# N32H7xx register map
Vendor: Nationstech Ltd.; File version: 1.0
CPU: CM7 r1p1, little endian, MPU, FPU, 4 interrupt priority bits
Registers are 32-bit, read-write, reset 0x0 unless marked. A register's access mark holds for its fields unless they carry their own. Offsets are from the block's base; [hi:lo] are bit positions; {n}, {i} and the like mark numbered series; 'fields as' and 'values as' point back to an identical list.

## CORDIC — CORDIC Processors
Base 0x400F1000
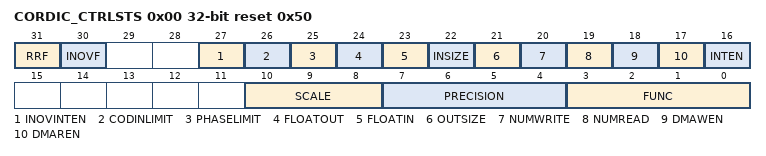
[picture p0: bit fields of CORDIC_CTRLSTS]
0x00 CORDIC_CTRLSTS reset 0x50 — CORDIC Control Status Register
  [31] RRF ro — Result Ready Flag
  [30] INOVF — Input Overflow Flag
  [27] INOVINTEN — Input Overflow Interrupt Control Bit
  [26] CODINLIMIT — Coordinate Output Limit Control
  [25] PHASELIMIT — Phase Output Limit Control
  [24] FLOATOUT — Floating-point Fixed-point Output Control
  [23] FLOATIN — Floating-point Fixed-point Input Control.
  [22] INSIZE — Input Data Width
  [21] OUTSIZE — Output Data Width
  [20] NUMWRITE — CORDIC_WDAT Register Parameter Count
  [19] NUMREAD — Number of results that can be read from the CORDIC_RDAT register
  [18] DMAWEN — DMA Write Request Enable
  [17] DMAREN — DMA Read Request Enable
  [16] INTEN — Interrupt Enable
  [10:8] SCALE — Scaling Factor
  [7:4] PRECISION — Iteration Count
  [3:0] FUNC — Functions
0x04 CORDIC_WDAT wo — CORDIC Write Data Register
  [31:0] WDAT — Write Data
0x08 CORDIC_RDAT ro — CORDIC Read Data Register
  [31:0] RDAT — Read Data

## DCMUA — DCMU processor A side
Base 0x400F7000
{0x0+4i} DCMUA_TXMSG{i} wo (i=0..3) — DCMU processor A transmit message register {i}
  [31:0] DATA — Transmit message data
{0x10+4i} DCMUA_RCVMSG{i} ro (i=0..3) — DCMU processor A receive message register {i}
  [31:0] DATA — Receive message data
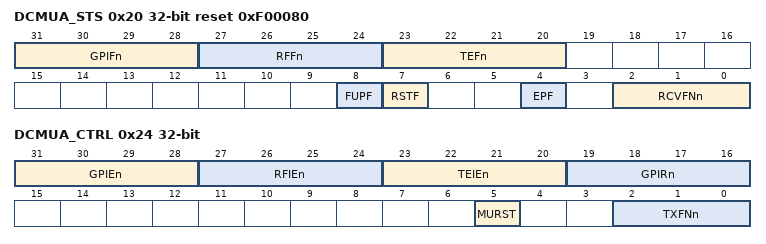
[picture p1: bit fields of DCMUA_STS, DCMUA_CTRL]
0x20 DCMUA_STS reset 0xF00080 — DCMU processor A status register
  [31:28] GPIFn — General interrupt request n pending flag
  [27:24] RFFn ro — Receive message register n full flag
  [23:20] TEFn ro — Transmit message register n empty flag
  [8] FUPF — Flags update pending flag
  [7] RSTF — Processor reset state
  [4] EPF — Event pending flag
  [2:0] RCVFNn ro — Receive flag number n
0x24 DCMUA_CTRL — DCMU processor A control register
  [31:28] GPIEn — General purpose interrupt request enable n
  [27:24] RFIEn — Receive full interrupt enable n
  [23:20] TEIEn — Transmit empty interrupt enable n
  [19:16] GPIRn — General purpose interrupt request n
  [5] MURST wo — DCMU reset
  [2:0] TXFNn — Processor to processor transmit flag number n

## DCMUB — DCMU processor B side
Base 0x400F8000
{0x0+4i} DCMUB_TXMSG{i} wo (i=0..3) — DCMU processor B transmit message register {i}
  [31:0] DATA — Transmit message data
{0x10+4i} DCMUB_RCVMSG{i} ro (i=0..3) — DCMU processor B receive message register {i}
  [31:0] DATA — Receive message data
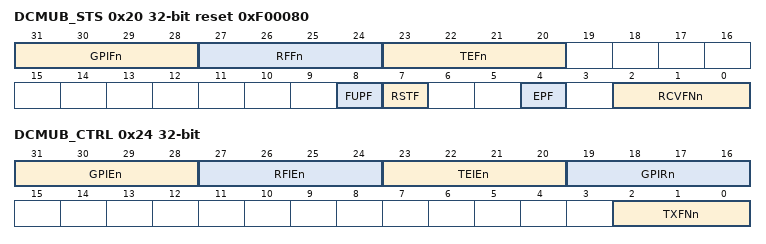
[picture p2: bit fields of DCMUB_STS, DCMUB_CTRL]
0x20 DCMUB_STS reset 0xF00080 — DCMU processor B status register
  [31:28] GPIFn — General interrupt request n pending flag
  [27:24] RFFn ro — Receive message register n full flag
  [23:20] TEFn ro — Transmit message register n empty flag
  [8] FUPF — Flags update pending flag
  [7] RSTF — Processor reset state
  [4] EPF — Event pending flag
  [2:0] RCVFNn ro — Receive flag number n
0x24 DCMUB_CTRL — DCMU processor B control register
  [31:28] GPIEn — General purpose interrupt request enable n
  [27:24] RFIEn — Receive full interrupt enable n
  [23:20] TEIEn — Transmit empty interrupt enable n
  [19:16] GPIRn — General purpose interrupt request n
  [2:0] TXFNn — Processor to processor transmit flag number n

## USB_HS1_Global — USB high speed dual role 1
Base 0x40100000
Same registers: USB_HS2_Global 0x40060000
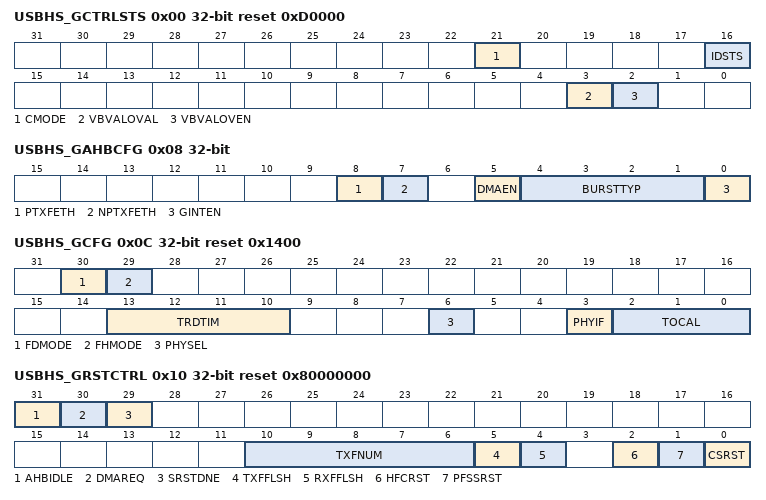
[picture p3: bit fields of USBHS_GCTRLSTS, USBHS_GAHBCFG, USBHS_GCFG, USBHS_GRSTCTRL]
0x00 USBHS_GCTRLSTS reset 0xD0000 — USBHS global control and status register
  [21] CMODE ro, [16] IDSTS ro, [3] VBVALOVAL, [2] VBVALOVEN
0x08 USBHS_GAHBCFG
  [8] PTXFETH, [7] NPTXFETH, [5] DMAEN, [4:1] BURSTTYP, [0] GINTEN
0x0C USBHS_GCFG reset 0x1400
  [30] FDMODE, [29] FHMODE, [13:10] TRDTIM, [6] PHYSEL, [3] PHYIF, [2:0] TOCAL
0x10 USBHS_GRSTCTRL reset 0x80000000
  [31] AHBIDLE ro, [30] DMAREQ ro, [29] SRSTDNE, [10:6] TXFNUM, [5] TXFFLSH, [4] RXFFLSH, [2] HFCRST, [1] PFSSRST, [0] CSRST
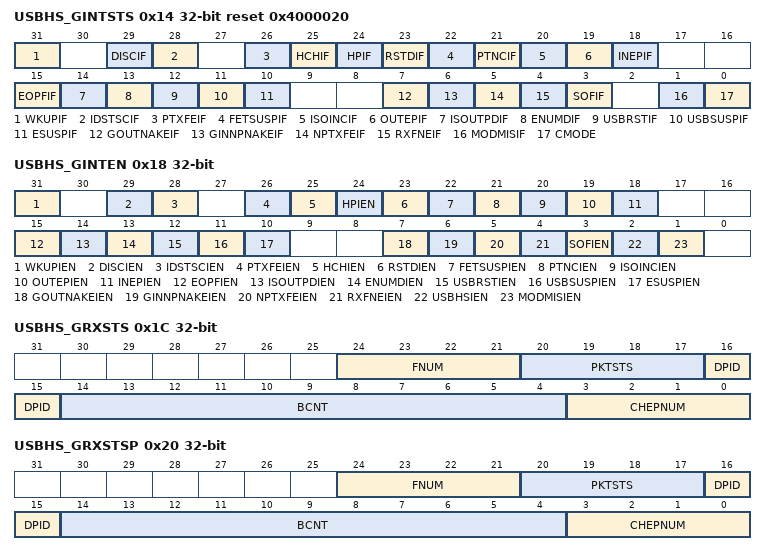
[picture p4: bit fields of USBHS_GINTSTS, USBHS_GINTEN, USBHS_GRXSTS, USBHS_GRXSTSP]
0x14 USBHS_GINTSTS reset 0x4000020
  [31] WKUPIF
  [29] DISCIF
  [28] IDSTSCIF
  [26] PTXFEIF ro
  [25] HCHIF ro — Host channels interrupt
  [24] HPIF ro
  [23] RSTDIF
  [22] FETSUSPIF
  [21] PTNCIF
  [20] ISOINCIF
  [19] OUTEPIF ro
  [18] INEPIF ro
  [15] EOPFIF
  [14] ISOUTPDIF
  [13] ENUMDIF
  [12] USBRSTIF
  [11] USBSUSPIF
  [10] ESUSPIF
  [7] GOUTNAKEIF ro
  [6] GINNPNAKEIF ro
  [5] NPTXFEIF ro
  [4] RXFNEIF ro
  [3] SOFIF
  [1] MODMISIF
  [0] CMODE ro
0x18 USBHS_GINTEN
  [31] WKUPIEN, [29] DISCIEN, [28] IDSTSCIEN, [26] PTXFEIEN, [25] HCHIEN, [24] HPIEN, [23] RSTDIEN, [22] FETSUSPIEN, [21] PTNCIEN, [20] ISOINCIEN, [19] OUTEPIEN, [18] INEPIEN, [15] EOPFIEN, [14] ISOUTPDIEN, [13] ENUMDIEN, [12] USBRSTIEN, [11] USBSUSPIEN, [10] ESUSPIEN, [7] GOUTNAKEIEN, [6] GINNPNAKEIEN, [5] NPTXFEIEN, [4] RXFNEIEN, [3] SOFIEN, [2] USBHSIEN, [1] MODMISIEN
0x1C USBHS_GRXSTS ro
  [24:21] FNUM, [20:17] PKTSTS, [16:15] DPID, [14:4] BCNT, [3:0] CHEPNUM
0x20 USBHS_GRXSTSP ro
  fields as USBHS_GRXSTS
0x24 USBHS_GRXFSIZ reset 0x400
  [10:0] RXFDEP
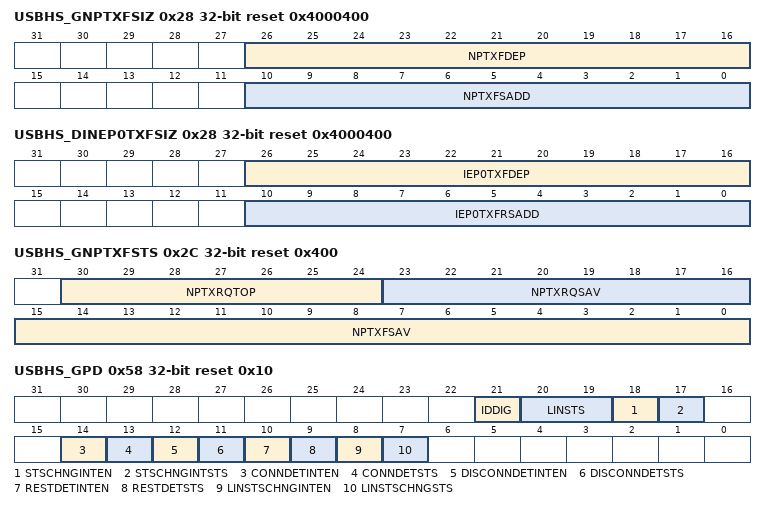
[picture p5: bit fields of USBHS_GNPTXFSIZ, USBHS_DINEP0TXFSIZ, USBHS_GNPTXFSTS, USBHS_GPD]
0x28 USBHS_GNPTXFSIZ reset 0x4000400
  [26:16] NPTXFDEP
  [10:0] NPTXFSADD — NNPTXFSADD
0x28 USBHS_DINEP0TXFSIZ reset 0x4000400 (alternate view of USBHS_GNPTXFSIZ) — EUSBHS_DINEP0TXFSIZ
  [26:16] IEP0TXFDEP, [10:0] IEP0TXFRSADD
0x2C USBHS_GNPTXFSTS ro reset 0x400
  [30:24] NPTXRQTOP, [23:16] NPTXRQSAV, [15:0] NPTXFSAV
0x3C USBHS_CID reset 0x3608
0x58 USBHS_GPD reset 0x10
  [21] IDDIG ro, [20:19] LINSTS ro, [18] STSCHNGINTEN, [17] STSCHNGINTSTS, [14] CONNDETINTEN, [13] CONNDETSTS, [12] DISCONNDETINTEN, [11] DISCONNDETSTS, [10] RESTDETINTEN, [9] RESTDETSTS, [8] LINSTSCHNGINTEN, [7] LINSTSCHNGSTS
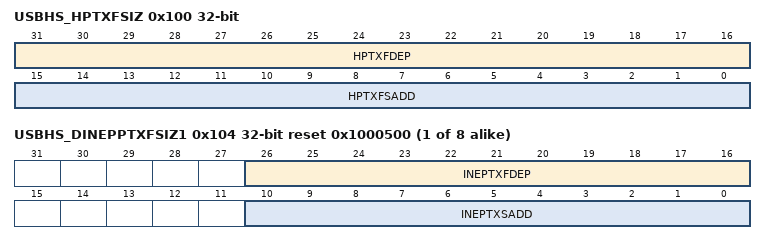
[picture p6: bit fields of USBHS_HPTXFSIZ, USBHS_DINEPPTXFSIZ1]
0x100 USBHS_HPTXFSIZ
  [31:16] HPTXFDEP, [15:0] HPTXFSADD
{0x100+4i} USBHS_DINEPPTXFSIZ{i} reset 0x1000500 (i=1..8)
  [26:16] INEPTXFDEP, [10:0] INEPTXSADD
